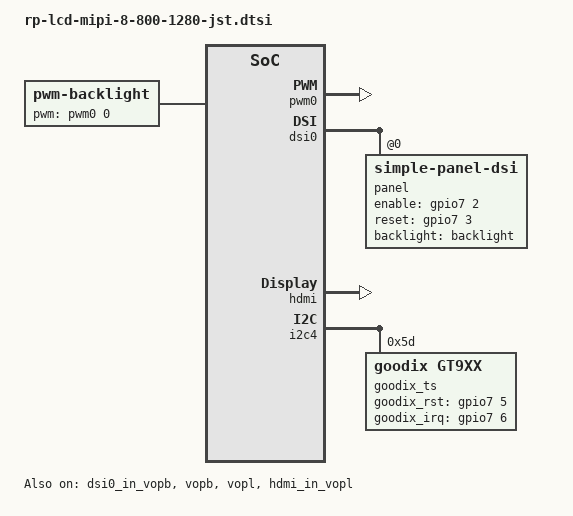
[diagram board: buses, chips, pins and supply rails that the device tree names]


/ {

	display-subsystem {
		status = "okay";

		ports = <&vopb_out>, <&vopl_out>;
		logo-memory-region = <&drm_logo>;

		route {
			route_edp: route-edp {
				status = "disabled";
				logo,uboot = "logo.bmp";
				logo,kernel = "logo.bmp";
				logo,mode = "center";
				charge_logo,mode = "center";
				connect = <&vopb_out_edp>;
			};

			route_dsi0: route-dsi0 {
				status = "disabled";
				logo,uboot = "logo.bmp";
				logo,kernel = "logo.bmp";
				logo,mode = "center";
				charge_logo,mode = "center";
				connect = <&vopb_out_dsi0>;
			};

			route_lvds: route-lvds {
				status = "disabled";
				logo,uboot = "logo.bmp";
				logo,kernel = "logo.bmp";
				logo,mode = "center";
				charge_logo,mode = "center";
				connect = <&vopb_out_lvds>;
			};

			route_hdmi: route-hdmi {
				status = "disabled";
				logo,uboot = "logo.bmp";
				logo,kernel = "logo.bmp";
				logo,mode = "center";
				charge_logo,mode = "center";
				connect = <&vopl_out_hdmi>;
			};
		};
	};
	
	backlight: backlight {
		status = "okay";
		compatible = "pwm-backlight";
		pwms = <&pwm0 0 25000 0>;
		brightness-levels = <
			  0   1   2   3   4   5   6   7
			  8   9  10  11  12  13  14  15
			 16  17  18  19  20  21  22  23
			 24  25  26  27  28  29  30  31
			 32  33  34  35  36  37  38  39
			 40  41  42  43  44  45  46  47
			 48  49  50  51  52  53  54  55
			 56  57  58  59  60  61  62  63
			 64  65  66  67  68  69  70  71
			 72  73  74  75  76  77  78  79
			 80  81  82  83  84  85  86  87
			 88  89  90  91  92  93  94  95
			 96  97  98  99 100 101 102 103
			104 105 106 107 108 109 110 111
			112 113 114 115 116 117 118 119
			120 121 122 123 124 125 126 127
			128 129 130 131 132 133 134 135
			136 137 138 139 140 141 142 143
			144 145 146 147 148 149 150 151
			152 153 154 155 156 157 158 159
			160 161 162 163 164 165 166 167
			168 169 170 171 172 173 174 175
			176 177 178 179 180 181 182 183
			184 185 186 187 188 189 190 191
			192 193 194 195 196 197 198 199
			200 201 202 203 204 205 206 207
			208 209 210 211 212 213 214 215
			216 217 218 219 220 221 222 223
			224 225 226 227 228 229 230 231
			232 233 234 235 236 237 238 239
			240 241 242 243 244 245 246 247
			248 249 250 251 252 253 254 255>;
		default-brightness-level = <255>;
	};
        //bill
        rpdzkj_config {
                compatible = "rp_config";
                user_version = "rpdzkj";
                system_rotate = "0";
                back_camera_rotate = "0";
                front_camera_rotate = "0";
                lcd_density = "160";
                language = "zh-CN";   //zh-CN //en-US
                time_zone = "Asia/Shanghai"; //Asia/Shanghai = +8   //Europe/London  = +1	//Africa/Casablanca	= +0;
                not_navigation_bar = "false";
                not_status_bar = "false";
                default_launcher = "true";
                has_root = "true";
                usb_not_permission = "true";  
                usb_camera_only_front = "false";
                gps_use = "false";
                gps_serial_port = "/dev/ttyS4";
                status = "okay";
        };
	
};
&pwm0 {
        status = "okay";
};
&dsi0 {
        status = "okay";
       rockchip,lane-rate = <480>;

        panel: panel {
                compatible = "simple-panel-dsi";
                reg = <0>;
                backlight = <&backlight>;
		cmd_later_reset = <0>;
                enable-gpios = <&gpio7 2 GPIO_ACTIVE_HIGH>;
                reset-gpios = <&gpio7 3 GPIO_ACTIVE_HIGH>;
		//power-supply = <&vcc_lcd>;
                dsi,flags = <(MIPI_DSI_MODE_VIDEO | MIPI_DSI_MODE_VIDEO_BURST |
                                MIPI_DSI_MODE_LPM | MIPI_DSI_MODE_EOT_PACKET)>;
                dsi,format = <MIPI_DSI_FMT_RGB888>;
                dsi,lanes = <4>;
                reset-delay-ms = <20>;
                init-delay-ms = <20>;
                enable-delay-ms = <120>;
                prepare-delay-ms = <120>;
                status = "okay";
		
               panel-init-sequence = [
			15 00 02 E0 00
			15 00 02 E1 93
			15 00 02 E2 65
			15 00 02 E3 F8
			15 00 02 80 03
			15 00 02 E0 01
			15 00 02 00 00
			15 00 02 01 6A
			15 00 02 03 00
			15 00 02 04 6C
			15 00 02 0C 74
			15 00 02 17 00
			15 00 02 18 D7
			15 00 02 19 01
			15 00 02 1A 00
			15 00 02 1B D7
			15 00 02 1C 01
			15 00 02 1F 70
			15 00 02 20 2D
			15 00 02 21 2D
			15 00 02 22 7E
			15 00 02 35 28
			15 00 02 37 19
			15 00 02 38 05
			15 00 02 39 00
			15 00 02 3A 01
			15 00 02 3C 7C
			15 00 02 3D FF
			15 00 02 3E FF
			15 00 02 3F 7F
			15 00 02 40 06
			15 00 02 41 A0
			15 00 02 43 1E
			15 00 02 44 0B
			15 00 02 45 28
			15 00 02 55 01
			15 00 02 57 A9
			15 00 02 59 0A
			15 00 02 5A 2E
			15 00 02 5B 1A
			15 00 02 5C 15
			15 00 02 5D 7F
			15 00 02 5E 57
			15 00 02 5F 43
			15 00 02 60 36
			15 00 02 61 31
			15 00 02 62 22
			15 00 02 63 27
			15 00 02 64 11
			15 00 02 65 2A
			15 00 02 66 2A
			15 00 02 67 2A
			15 00 02 68 49
			15 00 02 69 38
			15 00 02 6A 40
			15 00 02 6B 32
			15 00 02 6C 2E
			15 00 02 6D 21
			15 00 02 6E 10
			15 00 02 6F 02
			15 00 02 70 7F
			15 00 02 71 57
			15 00 02 72 43
			15 00 02 73 36
			15 00 02 74 31
			15 00 02 75 22
			15 00 02 76 27
			15 00 02 77 11
			15 00 02 78 2A
			15 00 02 79 2A
			15 00 02 7A 2A
			15 00 02 7B 49
			15 00 02 7C 38
			15 00 02 7D 40
			15 00 02 7E 32
			15 00 02 7F 2E
			15 00 02 80 21
			15 00 02 81 10
			15 00 02 82 02
			15 00 02 E0 02
			15 00 02 00 52
			15 00 02 01 55
			15 00 02 02 55
			15 00 02 03 50
			15 00 02 04 77
			15 00 02 05 57
			15 00 02 06 55
			15 00 02 07 4E
			15 00 02 08 4C
			15 00 02 09 5F
			15 00 02 0A 4A
			15 00 02 0B 48
			15 00 02 0C 55
			15 00 02 0D 46
			15 00 02 0E 44
			15 00 02 0F 40
			15 00 02 10 55
			15 00 02 11 55
			15 00 02 12 55
			15 00 02 13 55
			15 00 02 14 55
			15 00 02 15 55
			15 00 02 16 53
			15 00 02 17 55
			15 00 02 18 55
			15 00 02 19 51
			15 00 02 1A 77
			15 00 02 1B 57
			15 00 02 1C 55
			15 00 02 1D 4F
			15 00 02 1E 4D
			15 00 02 1F 5F
			15 00 02 20 4B
			15 00 02 21 49
			15 00 02 22 55
			15 00 02 23 47
			15 00 02 24 45
			15 00 02 25 41
			15 00 02 26 55
			15 00 02 27 55
			15 00 02 28 55
			15 00 02 29 55
			15 00 02 2A 55
			15 00 02 2B 55
			15 00 02 2C 13
			15 00 02 2D 15
			15 00 02 2E 15
			15 00 02 2F 01
			15 00 02 30 37
			15 00 02 31 17
			15 00 02 32 15
			15 00 02 33 0D
			15 00 02 34 0F
			15 00 02 35 15
			15 00 02 36 05
			15 00 02 37 07
			15 00 02 38 15
			15 00 02 39 09
			15 00 02 3A 0B
			15 00 02 3B 11
			15 00 02 3C 15
			15 00 02 3D 15
			15 00 02 3E 15
			15 00 02 3F 15
			15 00 02 40 15
			15 00 02 41 15                        
			15 00 02 42 12
			15 00 02 43 15
			15 00 02 44 15
			15 00 02 45 00
			15 00 02 46 37
			15 00 02 47 17
			15 00 02 48 15
			15 00 02 49 0C
			15 00 02 4A 0E
			15 00 02 4B 15
			15 00 02 4C 04
			15 00 02 4D 06
			15 00 02 4E 15
			15 00 02 4F 08
			15 00 02 50 0A
			15 00 02 51 10
			15 00 02 52 15
			15 00 02 53 15
			15 00 02 54 15
			15 00 02 55 15
			15 00 02 56 15
			15 00 02 57 15
			15 00 02 58 40
			15 00 02 5B 10
			15 00 02 5C 06
			15 00 02 5D 40
			15 00 02 5E 00
			15 00 02 5F 00
			15 00 02 60 40
			15 00 02 61 03
			15 00 02 62 04
			15 00 02 63 6C
			15 00 02 64 6C
			15 00 02 65 75
			15 00 02 66 08
			15 00 02 67 B4
			15 00 02 68 08
			15 00 02 69 6C
			15 00 02 6A 6C
			15 00 02 6B 0C
			15 00 02 6D 00
			15 00 02 6E 00
			15 00 02 6F 88
			15 00 02 75 BB
			15 00 02 76 00 
			15 00 02 77 05 
			15 00 02 78 2A
			15 00 02 E0 04
			15 00 02 09 11
			15 00 02 0E 48
			15 00 02 2B 2B
			15 00 02 2D 03
			15 00 02 2E 44 
			15 00 02 E0 05
			15 00 02 12 72      
			15 00 02 E0 00
			15 00 02 E6 02
			15 00 02 E7 0C
			
			05 78 01 11
			05 05 01 29
                ];
		panel-exit-sequence = [
			05 00 01 28
			05 78 01 10
		];

                disp_timings: display-timings {
                        native-mode = <&timing0>;

                        timing0: timing0 {
                                clock-frequency = <68000000>;
                                hactive = <800>;
                                vactive = <1280>;
                                hback-porch = <20>;
                                hfront-porch = <20>;
                                vback-porch = <8>;
                                vfront-porch = <30>;
                                hsync-len = <20>;
                                vsync-len = <4>;
                                hsync-active = <0>;
                                vsync-active = <0>;
                                de-active = <0>;
                                pixelclk-active = <0>;
                        };
                };
        };
};

&route_dsi0 {
        status = "okay";
};
&edp_in_vopl {
        status = "disabled";
};
&dsi0_in_vopl {
        status = "disabled";
};
&dsi1_in_vopl {
        status = "disabled";
};
&lvds_in_vopl {
        status = "disabled";
};

&edp_in_vopb {
        status = "disabled";
};
&dsi0_in_vopb {
        status = "okay";
};
&dsi1_in_vopb {
        status = "disabled";
};
&lvds_in_vopb {
        status = "disabled";
};

&vopb {
	status = "okay";
};

&vopb_mmu {
	status = "okay";
};

&vopl {
	status = "okay";
};

&vopl_mmu {
	status = "okay";
};

&hdmi {
	#address-cells = <1>;
	#size-cells = <0>;
	#sound-dai-cells = <0>;
	status = "okay";
};

&hdmi_in_vopl {
        status = "okay";
};
&hdmi_in_vopb {
        status = "disabled";
};

//TP
&i2c4 {
        status = "okay";
        goodix_ts@5d {
                compatible = "goodix,gt9xx";
                reg = <0x5d>;

                goodix_rst_gpio = <&gpio7 5 GPIO_ACTIVE_HIGH>;
                goodix_irq_gpio = <&gpio7 6 IRQ_TYPE_EDGE_FALLING>;

               goodix,cfg-group0 = [
                        46 20 03 00 05 05 05 00 01 08 28 05 50 32
						03 05 00 00 00 00 00 00 00 17 19 1C 14 8E
						2E 99 21 1F D9 0B 00 00 00 99 03 2D 00 00
						00 00 00 00 00 00 00 00 00 0F 23 94 C5 02
						07 00 00 04 DF 10 00 C0 13 00 A9 16 00 8E
						1B 00 7C 20 00 7C 00 00 00 00 00 00 00 00
						00 00 00 00 00 00 00 00 00 00 00 00 00 00
						00 00 00 00 00 00 00 00 00 00 00 00 00 00
						17 16 15 14 11 10 0F 0E 0D 0C 09 08 07 06
						05 04 01 00 FF FF 00 00 00 00 00 00 00 00
						00 00 00 02 04 06 07 08 0A 0C 0D 0F 10 11
						12 13 28 27 26 25 24 23 22 21 20 1F 1E 1C
						1B 19 FF FF FF FF 00 00 00 00 00 00 00 00
						00 00 19 01];
                goodix,cfg-group1 = [
                        46 20 03 00 05 05 05 00 01 08 28 05 50 32
						03 05 00 00 00 00 00 00 00 17 19 1C 14 8E
						2E 99 21 1F D9 0B 00 00 00 99 03 2D 00 00
						00 00 00 00 00 00 00 00 00 0F 23 94 C5 02
						07 00 00 04 DF 10 00 C0 13 00 A9 16 00 8E
						1B 00 7C 20 00 7C 00 00 00 00 00 00 00 00
						00 00 00 00 00 00 00 00 00 00 00 00 00 00
						00 00 00 00 00 00 00 00 00 00 00 00 00 00
						17 16 15 14 11 10 0F 0E 0D 0C 09 08 07 06
						05 04 01 00 FF FF 00 00 00 00 00 00 00 00
						00 00 00 02 04 06 07 08 0A 0C 0D 0F 10 11
						12 13 28 27 26 25 24 23 22 21 20 1F 1E 1C
						1B 19 FF FF FF FF 00 00 00 00 00 00 00 00
						00 00 19 01];
                goodix,cfg-group2 = [
                        46 20 03 00 05 05 05 00 01 08 28 05 50 32
						03 05 00 00 00 00 00 00 00 17 19 1C 14 8E
						2E 99 21 1F D9 0B 00 00 00 99 03 2D 00 00
						00 00 00 00 00 00 00 00 00 0F 23 94 C5 02
						07 00 00 04 DF 10 00 C0 13 00 A9 16 00 8E
						1B 00 7C 20 00 7C 00 00 00 00 00 00 00 00
						00 00 00 00 00 00 00 00 00 00 00 00 00 00
						00 00 00 00 00 00 00 00 00 00 00 00 00 00
						17 16 15 14 11 10 0F 0E 0D 0C 09 08 07 06
						05 04 01 00 FF FF 00 00 00 00 00 00 00 00
						00 00 00 02 04 06 07 08 0A 0C 0D 0F 10 11
						12 13 28 27 26 25 24 23 22 21 20 1F 1E 1C
						1B 19 FF FF FF FF 00 00 00 00 00 00 00 00
						00 00 19 01];
                goodix,cfg-group3 = [
                        46 20 03 00 05 05 05 00 01 08 28 05 50 32
						03 05 00 00 00 00 00 00 00 17 19 1C 14 8E
						2E 99 21 1F D9 0B 00 00 00 99 03 2D 00 00
						00 00 00 00 00 00 00 00 00 0F 23 94 C5 02
						07 00 00 04 DF 10 00 C0 13 00 A9 16 00 8E
						1B 00 7C 20 00 7C 00 00 00 00 00 00 00 00
						00 00 00 00 00 00 00 00 00 00 00 00 00 00
						00 00 00 00 00 00 00 00 00 00 00 00 00 00
						17 16 15 14 11 10 0F 0E 0D 0C 09 08 07 06
						05 04 01 00 FF FF 00 00 00 00 00 00 00 00
						00 00 00 02 04 06 07 08 0A 0C 0D 0F 10 11
						12 13 28 27 26 25 24 23 22 21 20 1F 1E 1C
						1B 19 FF FF FF FF 00 00 00 00 00 00 00 00
						00 00 19 01];
        };
};

